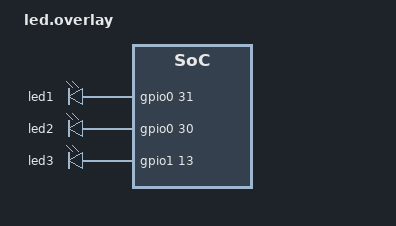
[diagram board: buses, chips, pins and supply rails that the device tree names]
/ {
    leds {
        compatible = "gpio-leds";
        led1: led_1 {
            gpios = <&gpio0 31 GPIO_ACTIVE_HIGH>;
        };
        led2: led_2 {
            gpios = <&gpio0 30 GPIO_ACTIVE_HIGH>;
        };
        led3: led_3 {
            gpios = <&gpio1 13 GPIO_ACTIVE_HIGH>;
        };
    };
};
